VERSION "1.0"

NS_ :

BS_:

BU_:
PCM1 FOO
VAL_TABLE_ Table3 16 "16" 7 "7" 2 "2" 0 "0" ;
VAL_TABLE_ Table2  ;
VAL_TABLE_ Table1 1 "One" 0 "Zero" ;

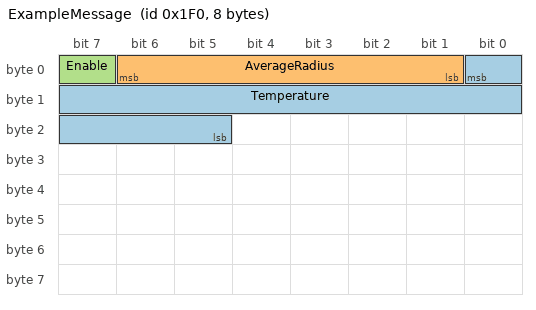
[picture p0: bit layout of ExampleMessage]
BO_ 496 ExampleMessage: 8 PCM1
 SG_ Temperature : 0|12@0- (0.01,250) [229.52|270.47] "degK"  PCM1,FOO
 SG_ AverageRadius : 6|6@0+ (0.1,0) [0|5] "m" Vector__XXX
 SG_ Enable : 7|1@0+ (1,0) [0|0] "-" Vector__XXX

BO_ 444 Message1: 8 Vector__XXX
 SG_ Signal1 : 0|8@1- (1,0) [0|0] "" Vector__XXX

CM_ BO_ 496 "Example message used as template in MotoHawk models.";
CM_ BO_ 444 "Test Message Created by Manz.";

VAL_ 496 Enable 0 "Disabled" 1 "Enabled" ;
VAL_ 444 Signal1 1 "One" 0 "Zero";
